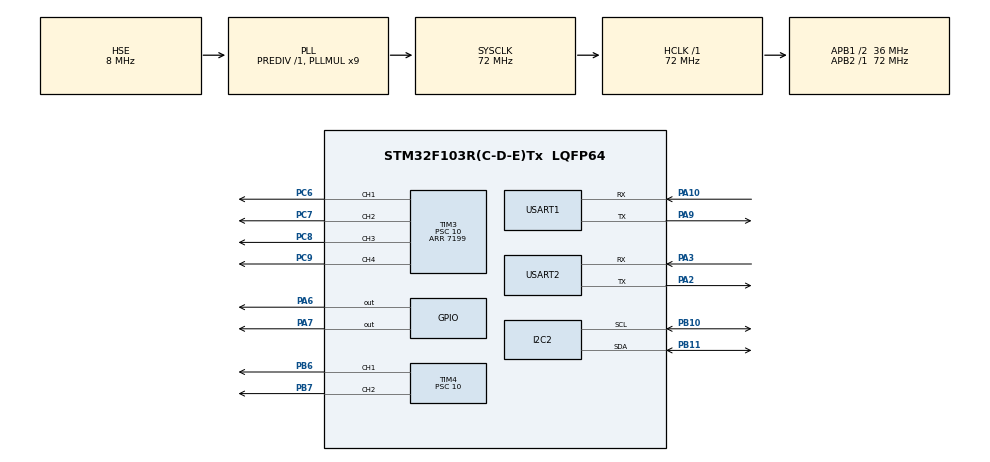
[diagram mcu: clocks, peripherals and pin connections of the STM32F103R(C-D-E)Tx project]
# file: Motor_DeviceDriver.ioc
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Mcu.Family=STM32F1
Mcu.Name=STM32F103R(C-D-E)Tx
Mcu.Package=LQFP64
NVIC.PriorityGroup=NVIC_PRIORITYGROUP_4
NVIC.TIM7_IRQn=true\:1\:0\:true\:false\:true\:false\:true\:true
NVIC.TimeBase=TIM7_IRQn
NVIC.TimeBaseIP=TIM7
NVIC.USART1_IRQn=true\:0\:0\:false\:false\:true\:true\:true\:true
PA10.Mode=Asynchronous
PA10.Signal=USART1_RX
PA13.Mode=Serial_Wire
PA13.Signal=SYS_JTMS-SWDIO
PA14.Mode=Serial_Wire
PA14.Signal=SYS_JTCK-SWCLK
PA2.Mode=Asynchronous
PA2.Signal=USART2_TX
PA3.Mode=Asynchronous
PA3.Signal=USART2_RX
PA6.Signal=GPIO_Output
PA7.Signal=GPIO_Output
PA9.Mode=Asynchronous
PA9.Signal=USART1_TX
PB10.Mode=I2C
PB10.Signal=I2C2_SCL
PB11.Mode=I2C
PB11.Signal=I2C2_SDA
PB6.Signal=S_TIM4_CH1
PB7.Signal=S_TIM4_CH2
PC6.Signal=S_TIM3_CH1
PC7.Signal=S_TIM3_CH2
PC8.Signal=S_TIM3_CH3
PC9.Signal=S_TIM3_CH4
PD0-OSC_IN.Mode=HSE-External-Oscillator
PD0-OSC_IN.Signal=RCC_OSC_IN
PD1-OSC_OUT.Mode=HSE-External-Oscillator
PD1-OSC_OUT.Signal=RCC_OSC_OUT
ProjectManager.HeapSize=0x200
ProjectManager.StackSize=0x400
ProjectManager.TargetToolchain=MDK-ARM V5.32
RCC.AHBFreq_Value=72000000
RCC.APB1CLKDivider=RCC_HCLK_DIV2
RCC.APB1Freq_Value=36000000
RCC.APB1TimFreq_Value=72000000
RCC.APB2Freq_Value=72000000
RCC.APB2TimFreq_Value=72000000
RCC.HCLKFreq_Value=72000000
RCC.PLLMUL=RCC_PLL_MUL9
RCC.PLLSourceVirtual=RCC_PLLSOURCE_HSE
RCC.SYSCLKFreq_VALUE=72000000
RCC.SYSCLKSource=RCC_SYSCLKSOURCE_PLLCLK
RCC.USBFreq_Value=72000000
SH.S_TIM3_CH1.0=TIM3_CH1,PWM Generation1 CH1
SH.S_TIM3_CH2.0=TIM3_CH2,PWM Generation2 CH2
SH.S_TIM3_CH3.0=TIM3_CH3,PWM Generation3 CH3
SH.S_TIM3_CH4.0=TIM3_CH4,PWM Generation4 CH4
SH.S_TIM4_CH1.0=TIM4_CH1,PWM Generation1 CH1
SH.S_TIM4_CH2.0=TIM4_CH2,PWM Generation2 CH2
TIM3.AutoReloadPreload=TIM_AUTORELOAD_PRELOAD_ENABLE
TIM3.Channel-PWM\ Generation1\ CH1=TIM_CHANNEL_1
TIM3.Channel-PWM\ Generation2\ CH2=TIM_CHANNEL_2
TIM3.Channel-PWM\ Generation3\ CH3=TIM_CHANNEL_3
TIM3.Channel-PWM\ Generation4\ CH4=TIM_CHANNEL_4
TIM3.Period=7199
TIM3.Prescaler=10
TIM3.Pulse-PWM\ Generation2\ CH2=0
TIM4.AutoReloadPreload=TIM_AUTORELOAD_PRELOAD_ENABLE
TIM4.Channel-PWM\ Generation1\ CH1=TIM_CHANNEL_1
TIM4.Channel-PWM\ Generation2\ CH2=TIM_CHANNEL_2
TIM4.Period=7199
TIM4.Prescaler=10
USART1.VirtualMode=VM_ASYNC
USART2.VirtualMode=VM_ASYNC
VP_SYS_VS_tim7.Mode=TIM7
board=custom

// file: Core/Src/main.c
/* USER CODE BEGIN Header */
/**
  ******************************************************************************
  * @file           : main.c
  * @brief          : Main program body
  ******************************************************************************
  * @attention
  *
  * Copyright (c) 2025 STMicroelectronics.
  * All rights reserved.
  *
  * This software is licensed under terms that can be found in the LICENSE file
  * in the root directory of this software component.
  * If no LICENSE file comes with this software, it is provided AS-IS.
  *
  ******************************************************************************
  */
/* USER CODE END Header */
#include "main.h"
#include "i2c.h"
#include "tim.h"
#include "usart.h"
#include "gpio.h"

/* USER CODE BEGIN Includes */
#include "oled.h"
#include "motor_control.h"
#include "mpu6050.h"
#include "stdint.h"
#include "stdio.h"
#include "string.h"
#include "FreeRTOS_main.h"

/* USER CODE END Includes */

void SystemClock_Config(void);

//void debug_flash_dump(void)
//{
//    char buf[64];
//    uint32_t *pf = (uint32_t*)0x0800FC00; // 如果你用的C8T6就是这个地址
//    for (int i = 0; i < 8; i++)
//    {
//        int len = sprintf(buf, "FLASH[%d]=0x%08lX\r\n", i, pf[i]);
//        HAL_UART_Transmit(&huart1, (uint8_t*)buf, len, 100);
//    }
//}

int main(void)
{

  /* MCU Configuration--------------------------------------------------------*/

  /* Reset of all peripherals, Initializes the Flash interface and the Systick. */
  HAL_Init();

  /* Configure the system clock */
  SystemClock_Config();

  /* Initialize all configured peripherals */
  MX_GPIO_Init();
  MX_TIM3_Init();
  MX_I2C2_Init();
  MX_TIM4_Init();
  MX_USART1_UART_Init();
  MX_USART2_UART_Init();
  /* USER CODE BEGIN 2 */
//	MPU6050_init(&hi2c2);
//	MPU6050 mpu_data;  // 姿态变量
debug_flash_dump();
FreeRTOS_Start();

  /* USER CODE END 2 */

  /* Infinite loop */
  /* USER CODE BEGIN WHILE */
  while (1)
	{
//  {  MPU6050_Get_Angle_Plus(&mpu_data);

//			  double Real_yaw   =  mpu_data.yaw;
//				double Real_pitch =  -mpu_data.roll;
//				double Real_row   =  mpu_data.pitch;
//
//        char uart_msg[100];
//        sprintf(uart_msg, "%.3f,%.3f,%.3f\n",
//        Real_yaw, Real_pitch, Real_row);
//        HAL_UART_Transmit(&huart1, (uint8_t*)uart_msg, strlen(uart_msg), 10);

//	Main_Loop();

    /* USER CODE END WHILE */

  }
}

void SystemClock_Config(void)
{
  RCC_OscInitTypeDef RCC_OscInitStruct = {0};
  RCC_ClkInitTypeDef RCC_ClkInitStruct = {0};

  /** Initializes the RCC Oscillators according to the specified parameters
  * in the RCC_OscInitTypeDef structure.
  */
  RCC_OscInitStruct.OscillatorType = RCC_OSCILLATORTYPE_HSE;
  RCC_OscInitStruct.HSEState = RCC_HSE_ON;
  RCC_OscInitStruct.HSEPredivValue = RCC_HSE_PREDIV_DIV1;
  RCC_OscInitStruct.HSIState = RCC_HSI_ON;
  RCC_OscInitStruct.PLL.PLLState = RCC_PLL_ON;
  RCC_OscInitStruct.PLL.PLLSource = RCC_PLLSOURCE_HSE;
  RCC_OscInitStruct.PLL.PLLMUL = RCC_PLL_MUL9;
  if (HAL_RCC_OscConfig(&RCC_OscInitStruct) != HAL_OK)
  {
    Error_Handler();
  }

  /** Initializes the CPU, AHB and APB buses clocks
  */
  RCC_ClkInitStruct.ClockType = RCC_CLOCKTYPE_HCLK|RCC_CLOCKTYPE_SYSCLK
                              |RCC_CLOCKTYPE_PCLK1|RCC_CLOCKTYPE_PCLK2;
  RCC_ClkInitStruct.SYSCLKSource = RCC_SYSCLKSOURCE_PLLCLK;
  RCC_ClkInitStruct.AHBCLKDivider = RCC_SYSCLK_DIV1;
  RCC_ClkInitStruct.APB1CLKDivider = RCC_HCLK_DIV2;
  RCC_ClkInitStruct.APB2CLKDivider = RCC_HCLK_DIV1;

  if (HAL_RCC_ClockConfig(&RCC_ClkInitStruct, FLASH_LATENCY_2) != HAL_OK)
  {
    Error_Handler();
  }
}

void HAL_TIM_PeriodElapsedCallback(TIM_HandleTypeDef *htim)
{
  if (htim->Instance == TIM7) {
    HAL_IncTick();
  }
}

void Error_Handler(void)
{
  __disable_irq();
  while (1)
  {
  }
}
